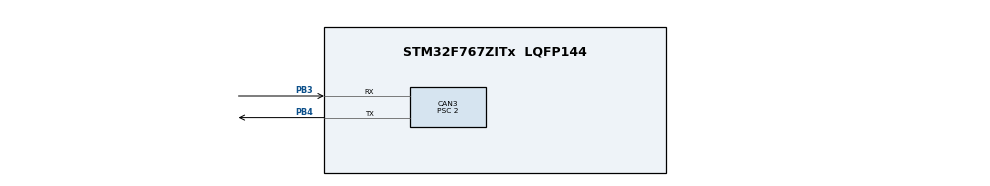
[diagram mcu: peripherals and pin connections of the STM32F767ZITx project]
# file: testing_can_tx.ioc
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CAN3.BS1=CAN_BS1_13TQ
CAN3.BS2=CAN_BS2_2TQ
CAN3.CalculateBaudRate=500000
CAN3.CalculateTimeBit=2000
CAN3.CalculateTimeQuantum=125.0
CAN3.Prescaler=2
Mcu.Family=STM32F7
Mcu.Name=STM32F767ZITx
Mcu.Package=LQFP144
NVIC.PriorityGroup=NVIC_PRIORITYGROUP_4
PB3.Mode=CAN_Activate
PB3.Signal=CAN3_RX
PB4.Mode=CAN_Activate
PB4.Signal=CAN3_TX
ProjectManager.HeapSize=0x200
ProjectManager.StackSize=0x400
ProjectManager.TargetToolchain=STM32CubeIDE
RCC.HSE_VALUE=25000000
RCC.HSI_VALUE=16000000
RCC.LSE_VALUE=32768
RCC.USBFreq_Value=96000000
RCC.VCOOutputFreq_Value=192000000
board=custom

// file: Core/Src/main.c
/* USER CODE BEGIN Header */
/**
  ******************************************************************************
  * @file           : main.c
  * @brief          : Main program body
  ******************************************************************************
  * @attention
  *
  * Copyright (c) 2024 STMicroelectronics.
  * All rights reserved.
  *
  * This software is licensed under terms that can be found in the LICENSE file
  * in the root directory of this software component.
  * If no LICENSE file comes with this software, it is provided AS-IS.
  *
  ******************************************************************************
  */
/* USER CODE END Header */
#include "main.h"

/* USER CODE BEGIN Includes */
#include "can_driver.h"
/* USER CODE END Includes */

CAN_HandleTypeDef hcan3;

void SystemClock_Config(void);
static void MX_GPIO_Init(void);
static void MX_CAN3_Init(void);

int main(void)
{

  /* MCU Configuration--------------------------------------------------------*/

  /* Reset of all peripherals, Initializes the Flash interface and the Systick. */
  HAL_Init();

  /* Configure the system clock */
  SystemClock_Config();

  /* Initialize all configured peripherals */
  MX_GPIO_Init();
  MX_CAN3_Init();
  /* USER CODE BEGIN 2 */
  HAL_CAN_Start(&hcan3);

  Data_Segment_t test_segment = {0x42, 1, 2};
  CAN_Frame_t tx_frame = CAN_frame_init(&hcan3, 0x42);
  CAN_set_segment(&tx_frame, test_segment, 0x4242);

  /* USER CODE END 2 */

  /* Infinite loop */
  /* USER CODE BEGIN WHILE */
  while (1)
  {
	  if (HAL_CAN_GetTxMailboxesFreeLevel(&hcan3)) {
		  CAN_send_frame(tx_frame);
	  }
	  HAL_GPIO_TogglePin(GPIOB, GPIO_PIN_0);
	  HAL_Delay(500);
    /* USER CODE END WHILE */

  }
}

void SystemClock_Config(void)
{
  RCC_OscInitTypeDef RCC_OscInitStruct = {0};
  RCC_ClkInitTypeDef RCC_ClkInitStruct = {0};

  /** Configure the main internal regulator output voltage
  */
  __HAL_RCC_PWR_CLK_ENABLE();
  __HAL_PWR_VOLTAGESCALING_CONFIG(PWR_REGULATOR_VOLTAGE_SCALE3);

  /** Initializes the RCC Oscillators according to the specified parameters
  * in the RCC_OscInitTypeDef structure.
  */
  RCC_OscInitStruct.OscillatorType = RCC_OSCILLATORTYPE_HSI;
  RCC_OscInitStruct.HSIState = RCC_HSI_ON;
  RCC_OscInitStruct.HSICalibrationValue = RCC_HSICALIBRATION_DEFAULT;
  RCC_OscInitStruct.PLL.PLLState = RCC_PLL_NONE;
  if (HAL_RCC_OscConfig(&RCC_OscInitStruct) != HAL_OK)
  {
    Error_Handler();
  }

  /** Initializes the CPU, AHB and APB buses clocks
  */
  RCC_ClkInitStruct.ClockType = RCC_CLOCKTYPE_HCLK|RCC_CLOCKTYPE_SYSCLK
                              |RCC_CLOCKTYPE_PCLK1|RCC_CLOCKTYPE_PCLK2;
  RCC_ClkInitStruct.SYSCLKSource = RCC_SYSCLKSOURCE_HSI;
  RCC_ClkInitStruct.AHBCLKDivider = RCC_SYSCLK_DIV1;
  RCC_ClkInitStruct.APB1CLKDivider = RCC_HCLK_DIV1;
  RCC_ClkInitStruct.APB2CLKDivider = RCC_HCLK_DIV1;

  if (HAL_RCC_ClockConfig(&RCC_ClkInitStruct, FLASH_LATENCY_0) != HAL_OK)
  {
    Error_Handler();
  }
}

static void MX_CAN3_Init(void)
{

  hcan3.Instance = CAN3;
  hcan3.Init.Prescaler = 2;
  hcan3.Init.Mode = CAN_MODE_NORMAL;
  hcan3.Init.SyncJumpWidth = CAN_SJW_1TQ;
  hcan3.Init.TimeSeg1 = CAN_BS1_13TQ;
  hcan3.Init.TimeSeg2 = CAN_BS2_2TQ;
  hcan3.Init.TimeTriggeredMode = DISABLE;
  hcan3.Init.AutoBusOff = DISABLE;
  hcan3.Init.AutoWakeUp = DISABLE;
  hcan3.Init.AutoRetransmission = DISABLE;
  hcan3.Init.ReceiveFifoLocked = DISABLE;
  hcan3.Init.TransmitFifoPriority = DISABLE;
  if (HAL_CAN_Init(&hcan3) != HAL_OK)
  {
    Error_Handler();
  }

}

static void MX_GPIO_Init(void)
{
  GPIO_InitTypeDef GPIO_InitStruct = {0};

  /* GPIO Ports Clock Enable */
  __HAL_RCC_GPIOB_CLK_ENABLE();
  __HAL_RCC_GPIOA_CLK_ENABLE();

  /*Configure GPIO pin Output Level */
  HAL_GPIO_WritePin(GPIOB, GPIO_PIN_0, GPIO_PIN_RESET);

  /*Configure GPIO pin : PB0 */
  GPIO_InitStruct.Pin = GPIO_PIN_0;
  GPIO_InitStruct.Mode = GPIO_MODE_OUTPUT_PP;
  GPIO_InitStruct.Pull = GPIO_NOPULL;
  GPIO_InitStruct.Speed = GPIO_SPEED_FREQ_LOW;
  HAL_GPIO_Init(GPIOB, &GPIO_InitStruct);

}

void Error_Handler(void)
{
  __disable_irq();
  while (1)
  {
  }
}
